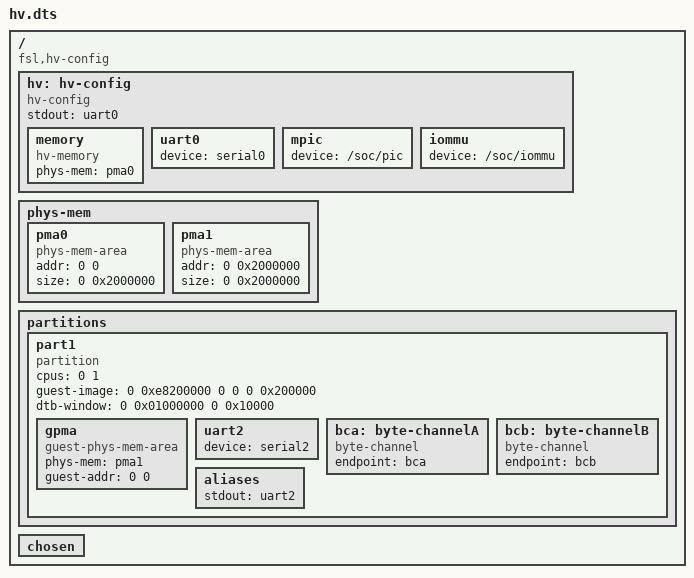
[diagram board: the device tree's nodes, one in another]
/dts-v1/;

/ {
	compatible = "fsl,hv-config";

	hv: hv-config {
		compatible = "hv-config";
		stdout = <&uart0>;
		
		memory {
			compatible = "hv-memory";
			phys-mem = <&pma0>;
		};

		uart0: uart0 {
			device = "serial0";
		};

		mpic {
			device = "/soc/pic";
		};

		iommu {
			device = "/soc/iommu";
		};
	};

	phys-mem {
		pma0: pma0 {
			compatible = "phys-mem-area";
			addr = <0 0>;
			size = <0 0x2000000>;
		};

		pma1: pma1 {
			compatible = "phys-mem-area";
			addr = <0 0x2000000>;
			size = <0 0x2000000>;
		};
	};

	partitions {
		part1 {
			compatible = "partition";
			cpus = <0 1>;
			guest-image = <0 0xe8200000 0 0 0 0x200000>;
			dtb-window = <0 0x01000000 0 0x10000>;

			gpma {
				compatible = "guest-phys-mem-area";
				phys-mem = <&pma1>;
				guest-addr = <0 0>;
			};

			uart2: uart2 {
				device = "serial2";
			};

			bca: byte-channelA {
				compatible = "byte-channel";
				endpoint = <&bca>;
			};

			bcb: byte-channelB {
				compatible = "byte-channel";
				endpoint = <&bcb>;
			};

			aliases {
				stdout = <&uart2>;
			};
		};
	};

	chosen {
	};
};
